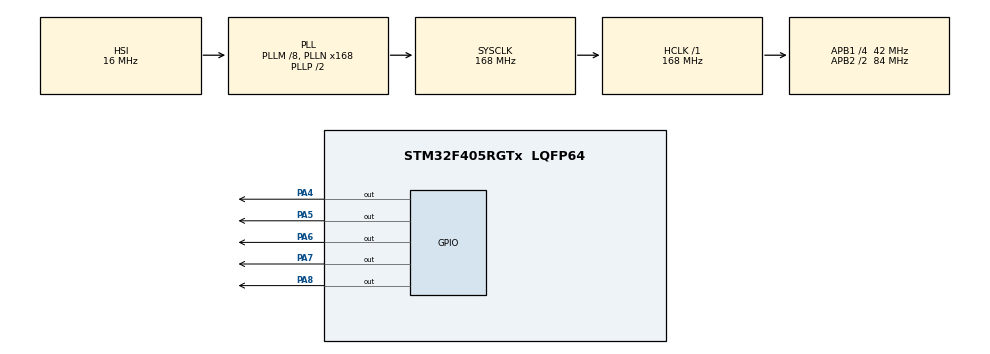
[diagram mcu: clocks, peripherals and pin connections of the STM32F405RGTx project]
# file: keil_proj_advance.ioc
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Mcu.Family=STM32F4
Mcu.Name=STM32F405RGTx
Mcu.Package=LQFP64
NVIC.PriorityGroup=NVIC_PRIORITYGROUP_4
NVIC.TIM3_IRQn=true\:0\:0\:false\:false\:true\:true\:true\:true
PA4.Signal=GPIO_Output
PA5.Signal=GPIO_Output
PA6.Signal=GPIO_Output
PA7.Signal=GPIO_Output
PA8.Signal=GPIO_Output
PH0-OSC_IN.Mode=HSE-External-Oscillator
PH0-OSC_IN.Signal=RCC_OSC_IN
PH1-OSC_OUT.Mode=HSE-External-Oscillator
PH1-OSC_OUT.Signal=RCC_OSC_OUT
ProjectManager.HeapSize=0x200
ProjectManager.StackSize=0x400
ProjectManager.TargetToolchain=MDK-ARM V5.32
RCC.48MHZClocksFreq_Value=84000000
RCC.AHBFreq_Value=168000000
RCC.APB1CLKDivider=RCC_HCLK_DIV4
RCC.APB1Freq_Value=42000000
RCC.APB1TimFreq_Value=84000000
RCC.APB2CLKDivider=RCC_HCLK_DIV2
RCC.APB2Freq_Value=84000000
RCC.APB2TimFreq_Value=168000000
RCC.CortexFreq_Value=168000000
RCC.HCLKFreq_Value=168000000
RCC.HSE_VALUE=25000000
RCC.HSI_VALUE=16000000
RCC.LSE_VALUE=32768
RCC.PLLM=8
RCC.PLLN=168
RCC.SYSCLKFreq_VALUE=168000000
RCC.SYSCLKSource=RCC_SYSCLKSOURCE_PLLCLK
RCC.VCOOutputFreq_Value=336000000
TIM3.Period=999
TIM3.Prescaler=83
VP_TIM3_VS_ClockSourceINT.Mode=Internal
board=custom

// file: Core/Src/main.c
/* USER CODE BEGIN Header */
/**
  ******************************************************************************
  * @file           : main.c
  * @brief          : Main program body
  ******************************************************************************
  * @attention
  *
  * Copyright (c) 2026 STMicroelectronics.
  * All rights reserved.
  *
  * This software is licensed under terms that can be found in the LICENSE file
  * in the root directory of this software component.
  * If no LICENSE file comes with this software, it is provided AS-IS.
  *
  ******************************************************************************
  */
/* USER CODE END Header */
#include "main.h"

/* USER CODE BEGIN Includes */
#include "led.h"
#include "buzzer.h"

/* USER CODE END Includes */

TIM_HandleTypeDef htim3;

void SystemClock_Config(void);
static void MX_GPIO_Init(void);
static void MX_TIM3_Init(void);

int main(void)
{

  /* MCU Configuration--------------------------------------------------------*/

  /* Reset of all peripherals, Initializes the Flash interface and the Systick. */
  HAL_Init();

  /* Configure the system clock */
  SystemClock_Config();

  /* Initialize all configured peripherals */
  MX_GPIO_Init();
  MX_TIM3_Init();
  /* USER CODE BEGIN 2 */
  /* 上电蜂鸣提示 */
  buzzer_on();
  HAL_Delay(100U);
  buzzer_off();

  /* 题目3完成后，在这里调用封装好的流水灯初始化/运行函数 */

  /* USER CODE END 2 */

  /* Infinite loop */
  while (1)
  {

    /* USER CODE BEGIN 3 */
    led_running();
  }
  /* USER CODE END 3 */
}

void SystemClock_Config(void)
{
  RCC_OscInitTypeDef RCC_OscInitStruct = {0};
  RCC_ClkInitTypeDef RCC_ClkInitStruct = {0};

  /** Configure the main internal regulator output voltage
  */
  __HAL_RCC_PWR_CLK_ENABLE();
  __HAL_PWR_VOLTAGESCALING_CONFIG(PWR_REGULATOR_VOLTAGE_SCALE1);

  /** Initializes the RCC Oscillators according to the specified parameters
  * in the RCC_OscInitTypeDef structure.
  */
  RCC_OscInitStruct.OscillatorType = RCC_OSCILLATORTYPE_HSI;
  RCC_OscInitStruct.HSIState = RCC_HSI_ON;
  RCC_OscInitStruct.HSICalibrationValue = RCC_HSICALIBRATION_DEFAULT;
  RCC_OscInitStruct.PLL.PLLState = RCC_PLL_ON;
  RCC_OscInitStruct.PLL.PLLSource = RCC_PLLSOURCE_HSI;
  RCC_OscInitStruct.PLL.PLLM = 8;
  RCC_OscInitStruct.PLL.PLLN = 168;
  RCC_OscInitStruct.PLL.PLLP = RCC_PLLP_DIV2;
  RCC_OscInitStruct.PLL.PLLQ = 4;
  if (HAL_RCC_OscConfig(&RCC_OscInitStruct) != HAL_OK)
  {
    Error_Handler();
  }

  /** Initializes the CPU, AHB and APB buses clocks
  */
  RCC_ClkInitStruct.ClockType = RCC_CLOCKTYPE_HCLK|RCC_CLOCKTYPE_SYSCLK
                              |RCC_CLOCKTYPE_PCLK1|RCC_CLOCKTYPE_PCLK2;
  RCC_ClkInitStruct.SYSCLKSource = RCC_SYSCLKSOURCE_PLLCLK;
  RCC_ClkInitStruct.AHBCLKDivider = RCC_SYSCLK_DIV1;
  RCC_ClkInitStruct.APB1CLKDivider = RCC_HCLK_DIV4;
  RCC_ClkInitStruct.APB2CLKDivider = RCC_HCLK_DIV2;

  if (HAL_RCC_ClockConfig(&RCC_ClkInitStruct, FLASH_LATENCY_5) != HAL_OK)
  {
    Error_Handler();
  }
}

static void MX_TIM3_Init(void)
{

  TIM_ClockConfigTypeDef sClockSourceConfig = {0};
  TIM_MasterConfigTypeDef sMasterConfig = {0};

  htim3.Instance = TIM3;
  htim3.Init.Prescaler = 83;
  htim3.Init.CounterMode = TIM_COUNTERMODE_UP;
  htim3.Init.Period = 999;
  htim3.Init.ClockDivision = TIM_CLOCKDIVISION_DIV1;
  htim3.Init.AutoReloadPreload = TIM_AUTORELOAD_PRELOAD_DISABLE;
  if (HAL_TIM_Base_Init(&htim3) != HAL_OK)
  {
    Error_Handler();
  }
  sClockSourceConfig.ClockSource = TIM_CLOCKSOURCE_INTERNAL;
  if (HAL_TIM_ConfigClockSource(&htim3, &sClockSourceConfig) != HAL_OK)
  {
    Error_Handler();
  }
  sMasterConfig.MasterOutputTrigger = TIM_TRGO_RESET;
  sMasterConfig.MasterSlaveMode = TIM_MASTERSLAVEMODE_DISABLE;
  if (HAL_TIMEx_MasterConfigSynchronization(&htim3, &sMasterConfig) != HAL_OK)
  {
    Error_Handler();
  }

}

static void MX_GPIO_Init(void)
{
  GPIO_InitTypeDef GPIO_InitStruct = {0};

  /* GPIO Ports Clock Enable */
  __HAL_RCC_GPIOH_CLK_ENABLE();
  __HAL_RCC_GPIOA_CLK_ENABLE();

  /*Configure GPIO pin Output Level */
  HAL_GPIO_WritePin(GPIOA, GPIO_PIN_4|GPIO_PIN_5|GPIO_PIN_6|GPIO_PIN_7
                          |GPIO_PIN_8, GPIO_PIN_RESET);

  /*Configure GPIO pins : PA4 PA5 PA6 PA7
                           PA8 */
  GPIO_InitStruct.Pin = GPIO_PIN_4|GPIO_PIN_5|GPIO_PIN_6|GPIO_PIN_7
                          |GPIO_PIN_8;
  GPIO_InitStruct.Mode = GPIO_MODE_OUTPUT_PP;
  GPIO_InitStruct.Pull = GPIO_NOPULL;
  GPIO_InitStruct.Speed = GPIO_SPEED_FREQ_LOW;
  HAL_GPIO_Init(GPIOA, &GPIO_InitStruct);

}

void Error_Handler(void)
{
  __disable_irq();
  while (1)
  {
  }
}
